# ATtiny15 device description
Architecture: AVR8; Family: tinyAVR
Programming and debug interfaces: ISP, HVSP
Registers are 8-bit, access not given, no defined reset value unless marked. A register's access mark holds for its fields unless they carry their own. Offsets are from the block's base; lines under a group give offsets from that group; [hi:lo] are bit positions; {n}, {i} and the like mark numbered series; 'fields as' and 'values as' point back to an identical list; <NAME> marks a mode.

## Ordering variants
ATtiny15L-1SC: SOIC8, up to 1.6 MHz, 0 to 70 C, 2.7 to 5.5 V
ATtiny15L-1PC: PDIP8, up to 1.6 MHz, 0 to 70 C, 2.7 to 5.5 V
ATtiny15L-1SI: SOIC8, up to 1.6 MHz, -40 to 85 C, 2.7 to 5.5 V
ATtiny15L-1PI: PDIP8, up to 1.6 MHz, -40 to 85 C, 2.7 to 5.5 V

## Memory
prog space: start 0x0000 size 0x0400, little endian
  0x0000 FLASH size 0x0400 flash, rw, executable, page 0x80
signatures space: start 0 size 3, little endian
  0 SIGNATURES size 3 signatures, ro
fuses space: start 0 size 0x0001, little endian
  0 FUSES size 0x0001 fuses, rw
lockbits space: start 0 size 0x0001, little endian
  0 LOCKBITS size 0x0001 lockbits, rw
data space: start 0x0000 size 0x0040, little endian
  0 IO size 0x0040 io, rw
eeprom space: start 0x0000 size 0x0040, little endian
  0x0000 EEPROM size 0x0040 eeprom, rw, page 0x02
osccal space: start 0 size 1, little endian
  0 OSCCAL size 1 osccal, ro

## Peripheral instances (address, pins/pin function, parameters)
ADC at 0x00 — Analog-to-Digital Converter
AC at 0x00 — Analog Comparator
EEPROM at 0x00
PORTB at 0x00 — I/O Port
TC0 at 0x00 — Timer/Counter, 8-bit
TC1 at 0x00 — Timer/Counter, 8-bit
WDT at 0x00 — Watchdog Timer
CPU at 0x00 — CPU Registers
  parameters: CORE_VERSION=V0E
EXINT at 0x00 — External Interrupts
FUSE at 0 in fuses — Fuses
LOCKBIT at 0 in lockbits — Lockbits

## Interrupts
0 RESET — External Reset, Power-on Reset and Watchdog Reset
1 INT0 — External Interrupt 0
2 IO_PINS — External Interrupt Request 0
3 TIMER1_COMP — Timer/Counter1 Compare Match
4 TIMER1_OVF — Timer/Counter1 Overflow
5 TIMER0_OVF — Timer/Counter0 Overflow
6 EE_RDY — EEPROM Ready
7 ANA_COMP — Analog Comparator
8 ADC — ADC Conversion Ready

## Properties
SIGNATURES: SIGNATURE0=0x1e, SIGNATURE1=0x90, SIGNATURE2=0x06

## FUSE — Fuses
Instances: FUSE 0 in fuses
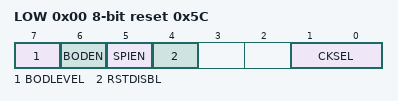
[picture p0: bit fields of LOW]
0x00 LOW reset 0x5C
  [7] BODLEVEL — Brown-out Detection Level
    1=2V7 (Brown-out detection at VCC=2.7 V); 0=4V0 (Brown-out detection at VCC=4.0 V)
  [6] BODEN — Brown-out detection enabled
  [5] SPIEN — Serial program downloading (SPI) enabled
  [4] RSTDISBL — External reset function of PB5 disabled
  [1:0] CKSEL — Clock Select
    3=VQUICKPWR (Very quickly rising power); 2=QUICKPWR (Quickly rising power); 1=SLOWPWR (Slowly rising power); 0=SLOWPWR (Slowly rising power)

## LOCKBIT — Lockbits
Instances: LOCKBIT 0 in lockbits
0x00 LOCKBIT reset 0xFF
  [2:1] LB — Memory Lock
    0=PROG_VER_DISABLED (Further programming and verification disabled); 1=PROG_DISABLED (Further programming disabled); 3=NO_LOCK (No memory lock features enabled)

## ADC — Analog-to-Digital Converter
Instances: ADC 0x00
0x04 ADC 16-bit — ADC Data Register Bytes
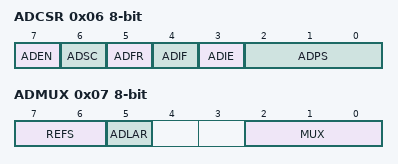
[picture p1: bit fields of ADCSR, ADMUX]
0x06 ADCSR — The ADC Control and Status register
  [7] ADEN — ADC Enable
  [6] ADSC — ADC Start Conversion
  [5] ADFR — ADC Free Running Select
  [4] ADIF — ADC Interrupt Flag
  [3] ADIE — ADC Interrupt Enable
  [2:0] ADPS — ADC Prescaler Select Bits
    0=2; 1=2; 2=4; 3=8; 4=16; 5=32; 6=64; 7=128
0x07 ADMUX — The ADC multiplexer Selection Register
  [7:6] REFS — Reference Selection Bits
    0=AVCC; 1=AREF; 2=INTERNAL_VOLTAGE_REFERANCE (Internal Voltage Reference); 3=INTERNAL_VOLTAGE_REFERENCE_WITH_EXTERNAL_CAPACITOR_AT_AREF_PIN
  [5] ADLAR — Left Adjust Result
  [2:0] MUX — Analog Channel and Gain Selection Bits

## AC — Analog Comparator
Instances: AC 0x00
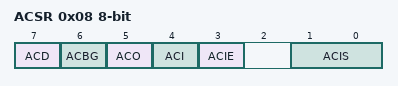
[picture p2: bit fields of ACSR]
0x08 ACSR — Analog Comparator Control And Status Register
  [7] ACD — Analog Comparator Disable
  [6] ACBG — Analog Comparator Bandgap Select
  [5] ACO — Analog Compare Output
  [4] ACI — Analog Comparator Interrupt Flag
  [3] ACIE — Analog Comparator Interrupt Enable
  [1:0] ACIS — Analog Comparator Interrupt Mode Select bits
    0=INTERRUPT_ON_TOGGLE; 2=INTERRUPT_ON_FALLING_EDGE; 3=INTERRUPT_ON_RISING_EDGE
